# GD32A72_A74x register map
File version: 1.0
CPU: CM7 r2p1, little endian, MPU, FPU, DSP, 4 interrupt priority bits
Registers are 32-bit, read-write, reset 0x0 unless marked. A register's access mark holds for its fields unless they carry their own. Offsets are from the block's base; [hi:lo] are bit positions.

## ENET_MMC
Base 0x4000A700
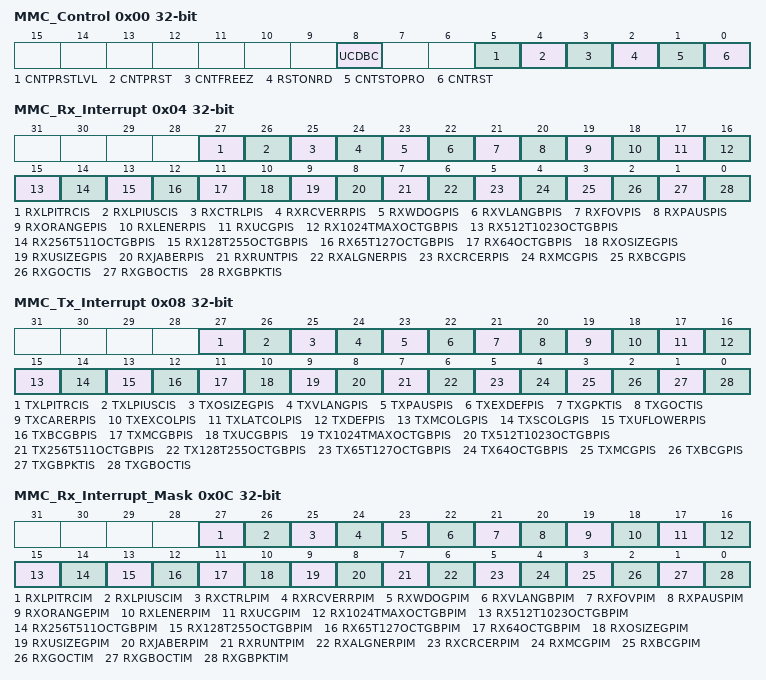
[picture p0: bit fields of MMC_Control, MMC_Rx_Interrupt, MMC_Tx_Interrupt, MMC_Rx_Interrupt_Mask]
0x00 MMC_Control
  [8] UCDBC — Update MMC Counters For Dropped Broadcast Packets
    0=DISABLE (Disabled); 1=ENABLE (Enabled)
  [5] CNTPRSTLVL — Full-Half Preset
    0=DISABLE (Disabled); 1=ENABLE (Enabled)
  [4] CNTPRST — Counters Preset
    0=DISABLE (Disabled); 1=ENABLE (Enabled)
  [3] CNTFREEZ — MMC Counter Freeze
    0=DISABLE (Disabled); 1=ENABLE (Enabled)
  [2] RSTONRD — Reset On Read
    0=DISABLE (Disabled); 1=ENABLE (Enabled)
  [1] CNTSTOPRO — Counter Stop Rollover
    0=DISABLE (Disabled); 1=ENABLE (Enabled)
  [0] CNTRST — Counters Reset
    0=DISABLE (Counters are not reset); 1=ENABLE (All counters are reset)
0x04 MMC_Rx_Interrupt ro — MMC Receive Interrupt
  [all] fields
    0=INACTIVE (Not detected); 1=ACTIVE (Detected)
  [27] RXLPITRCIS — MMC Receive LPI transition counter interrupt status
  [26] RXLPIUSCIS — MMC Receive LPI microsecond counter interrupt status
  [25] RXCTRLPIS — MMC Receive Control Packet Counter Interrupt Status
  [24] RXRCVERRPIS — MMC Receive Error Packet Counter Interrupt Status
  [23] RXWDOGPIS — MMC Receive Watchdog Error Packet Counter Interrupt Status
  [22] RXVLANGBPIS — MMC Receive VLAN Good Bad Packet Counter Interrupt Status
  [21] RXFOVPIS — MMC Receive FIFO Overflow Packet Counter Interrupt Status
  [20] RXPAUSPIS — MMC Receive Pause Packet Counter Interrupt Status
  [19] RXORANGEPIS — MMC Receive Out-Of-Range Error Packet Counter Interrupt Status
  [18] RXLENERPIS — MMC Receive Length Error Packet Counter Interrupt Status
  [17] RXUCGPIS — MMC Receive Unicast Good Packet Counter Interrupt Status
  [16] RX1024TMAXOCTGBPIS — MMC Receive 1024 To Maximum Octet Good Bad Packet Counter Interrupt Status
  [15] RX512T1023OCTGBPIS — MMC Receive 512 To 1023 Octet Good Bad Packet Counter Interrupt Status
  [14] RX256T511OCTGBPIS — MMC Receive 256 To 511 Octet Good Bad Packet Counter Interrupt Status
  [13] RX128T255OCTGBPIS — MMC Receive 128 To 255 Octet Good Bad Packet Counter Interrupt Status
  [12] RX65T127OCTGBPIS — MMC Receive 65 To 127 Octet Good Bad Packet Counter Interrupt Status
  [11] RX64OCTGBPIS — MMC Receive 64 Octet Good Bad Packet Counter Interrupt Status
  [10] RXOSIZEGPIS — MMC Receive Oversize Good Packet Counter Interrupt Status
  [9] RXUSIZEGPIS — MMC Receive Undersize Good Packet Counter Interrupt Status
  [8] RXJABERPIS — MMC Receive Jabber Error Packet Counter Interrupt Status
  [7] RXRUNTPIS — MMC Receive Runt Packet Counter Interrupt Status
  [6] RXALGNERPIS — MMC Receive Alignment Error Packet Counter Interrupt Status
  [5] RXCRCERPIS — MMC Receive CRC Error Packet Counter Interrupt Status
  [4] RXMCGPIS — MMC Receive Multicast Good Packet Counter Interrupt Status
  [3] RXBCGPIS — MMC Receive Broadcast Good Packet Counter Interrupt Status
  [2] RXGOCTIS — MMC Receive Good Octet Counter Interrupt Status
  [1] RXGBOCTIS — MMC Receive Good Bad Octet Counter Interrupt Status
  [0] RXGBPKTIS — MMC Receive Good Bad Packet Counter Interrupt Status
0x08 MMC_Tx_Interrupt ro — MMC Transmit Interrupt
  [all] fields
    0=INACTIVE (Not detected); 1=ACTIVE (Detected)
  [27] TXLPITRCIS — MMC Transmit LPI transition counter interrupt status
  [26] TXLPIUSCIS — MMC Transmit LPI microsecond counter interrupt status
  [25] TXOSIZEGPIS — MMC Transmit Oversize Good Packet Counter Interrupt Status
  [24] TXVLANGPIS — MMC Transmit VLAN Good Packet Counter Interrupt Status
  [23] TXPAUSPIS — MMC Transmit Pause Packet Counter Interrupt Status
  [22] TXEXDEFPIS — MMC Transmit Excessive Deferral Packet Counter Interrupt Status
  [21] TXGPKTIS — MMC Transmit Good Packet Counter Interrupt Status
  [20] TXGOCTIS — MMC Transmit Good Octet Counter Interrupt Status
  [19] TXCARERPIS — MMC Transmit Carrier Error Packet Counter Interrupt Status
  [18] TXEXCOLPIS — MMC Transmit Excessive Collision Packet Counter Interrupt Status
  [17] TXLATCOLPIS — MMC Transmit Late Collision Packet Counter Interrupt Status
  [16] TXDEFPIS — MMC Transmit Deferred Packet Counter Interrupt Status
  [15] TXMCOLGPIS — MMC Transmit Multiple Collision Good Packet Counter Interrupt Status
  [14] TXSCOLGPIS — MMC Transmit Single Collision Good Packet Counter Interrupt Status
  [13] TXUFLOWERPIS — MMC Transmit Underflow Error Packet Counter Interrupt Status
  [12] TXBCGBPIS — MMC Transmit Broadcast Good Bad Packet Counter Interrupt Status
  [11] TXMCGBPIS — MMC Transmit Multicast Good Bad Packet Counter Interrupt Status
  [10] TXUCGBPIS — MMC Transmit Unicast Good Bad Packet Counter Interrupt Status
  [9] TX1024TMAXOCTGBPIS — MMC Transmit 1024 To Maximum Octet Good Bad Packet Counter Interrupt Status
  [8] TX512T1023OCTGBPIS — MMC Transmit 512 To 1023 Octet Good Bad Packet Counter Interrupt Status
  [7] TX256T511OCTGBPIS — MMC Transmit 256 To 511 Octet Good Bad Packet Counter Interrupt Status
  [6] TX128T255OCTGBPIS — MMC Transmit 128 To 255 Octet Good Bad Packet Counter Interrupt Status
  [5] TX65T127OCTGBPIS — MMC Transmit 65 To 127 Octet Good Bad Packet Counter Interrupt Status
  [4] TX64OCTGBPIS — MMC Transmit 64-Octet Good Bad Packet Counter Interrupt Status
  [3] TXMCGPIS — MMC Transmit Multicast Good Packet Counter Interrupt Status
  [2] TXBCGPIS — MMC Transmit Broadcast Good Packet Counter Interrupt Status
  [1] TXGBPKTIS — MMC Transmit Good Bad Packet Counter Interrupt Status
  [0] TXGBOCTIS — MMC Transmit Good Bad Octet Counter Interrupt Status
0x0C MMC_Rx_Interrupt_Mask — MMC Receive Interrupt Mask
  [27] RXLPITRCIM — MMC Receive LPI transition counter interrupt Mask
    0=INACTIVE (Not detected); 1=ACTIVE (Detected)
  [26] RXLPIUSCIM — MMC Receive LPI microsecond counter interrupt Mask
    0=INACTIVE (Not detected); 1=ACTIVE (Detected)
  [25] RXCTRLPIM — MMC Receive Control Packet Counter Interrupt Mask
    0=DISABLE (Disabled); 1=ENABLE (Enabled)
  [24] RXRCVERRPIM — MMC Receive Error Packet Counter Interrupt Mask
    0=DISABLE (Disabled); 1=ENABLE (Enabled)
  [23] RXWDOGPIM — MMC Receive Watchdog Error Packet Counter Interrupt Mask
    0=DISABLE (Disabled); 1=ENABLE (Enabled)
  [22] RXVLANGBPIM — MMC Receive VLAN Good Bad Packet Counter Interrupt Mask
    0=DISABLE (Disabled); 1=ENABLE (Enabled)
  [21] RXFOVPIM — MMC Receive FIFO Overflow Packet Counter Interrupt Mask
    0=DISABLE (Disabled); 1=ENABLE (Enabled)
  [20] RXPAUSPIM — MMC Receive Pause Packet Counter Interrupt Mask
    0=DISABLE (Disabled); 1=ENABLE (Enabled)
  [19] RXORANGEPIM — MMC Receive Out-Of-Range Error Packet Counter Interrupt Mask
    0=DISABLE (Disabled); 1=ENABLE (Enabled)
  [18] RXLENERPIM — MMC Receive Length Error Packet Counter Interrupt Mask
    0=DISABLE (Disabled); 1=ENABLE (Enabled)
  [17] RXUCGPIM — MMC Receive Unicast Good Packet Counter Interrupt Mask
    0=DISABLE (Disabled); 1=ENABLE (Enabled)
  [16] RX1024TMAXOCTGBPIM — MMC Receive 1024 To Maximum Octet Good Bad Packet Counter Interrupt Mask
    0=DISABLE (Disabled); 1=ENABLE (Enabled)
  [15] RX512T1023OCTGBPIM — MMC Receive 512 To 1023 Octet Good Bad Packet Counter Interrupt Mask
    0=DISABLE (Disabled); 1=ENABLE (Enabled)
  [14] RX256T511OCTGBPIM — MMC Receive 256 To 511 Octet Good Bad Packet Counter Interrupt Mask
    0=DISABLE (Disabled); 1=ENABLE (Enabled)
  [13] RX128T255OCTGBPIM — MMC Receive 128 To 255 Octet Good Bad Packet Counter Interrupt Mask
    0=DISABLE (Disabled); 1=ENABLE (Enabled)
  [12] RX65T127OCTGBPIM — MMC Receive 65 To 127 Octet Good Bad Packet Counter Interrupt Mask
    0=DISABLE (Disabled); 1=ENABLE (Enabled)
  [11] RX64OCTGBPIM — MMC Receive 64-Octet Good Bad Packet Counter Interrupt Mask
    0=DISABLE (Disabled); 1=ENABLE (Enabled)
  [10] RXOSIZEGPIM — MMC Receive Oversize Good Packet Counter Interrupt Mask
    0=DISABLE (Disabled); 1=ENABLE (Enabled)
  [9] RXUSIZEGPIM — MMC Receive Undersize Good Packet Counter Interrupt Mask
    0=DISABLE (Disabled); 1=ENABLE (Enabled)
  [8] RXJABERPIM — MMC Receive Jabber Error Packet Counter Interrupt Mask
    0=DISABLE (Disabled); 1=ENABLE (Enabled)
  [7] RXRUNTPIM — MMC Receive Runt Packet Counter Interrupt Mask
    0=DISABLE (Disabled); 1=ENABLE (Enabled)
  [6] RXALGNERPIM — MMC Receive Alignment Error Packet Counter Interrupt Mask
    0=DISABLE (Disabled); 1=ENABLE (Enabled)
  [5] RXCRCERPIM — MMC Receive CRC Error Packet Counter Interrupt Mask
    0=DISABLE (Disabled); 1=ENABLE (Enabled)
  [4] RXMCGPIM — MMC Receive Multicast Good Packet Counter Interrupt Mask
    0=DISABLE (Disabled); 1=ENABLE (Enabled)
  [3] RXBCGPIM — MMC Receive Broadcast Good Packet Counter Interrupt Mask
    0=DISABLE (Disabled); 1=ENABLE (Enabled)
  [2] RXGOCTIM — MMC Receive Good Octet Counter Interrupt Mask
    0=DISABLE (Disabled); 1=ENABLE (Enabled)
  [1] RXGBOCTIM — MMC Receive Good Bad Octet Counter Interrupt Mask
    0=DISABLE (Disabled); 1=ENABLE (Enabled)
  [0] RXGBPKTIM — MMC Receive Good Bad Packet Counter Interrupt Mask
    0=DISABLE (Disabled); 1=ENABLE (Enabled)
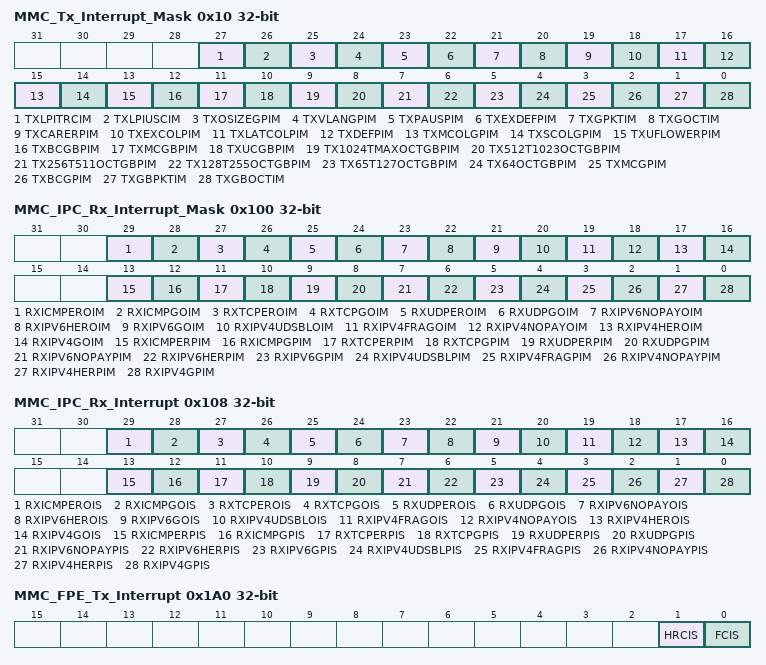
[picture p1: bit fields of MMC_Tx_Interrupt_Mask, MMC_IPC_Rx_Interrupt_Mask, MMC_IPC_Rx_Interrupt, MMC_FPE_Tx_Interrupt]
0x10 MMC_Tx_Interrupt_Mask — MMC Transmit Interrupt Mask
  [27] TXLPITRCIM — MMC Transmit LPI transition counter interrupt Mask
    0=INACTIVE (Not detected); 1=ACTIVE (Detected)
  [26] TXLPIUSCIM — MMC Transmit LPI microsecond counter interrupt Mask
    0=INACTIVE (Not detected); 1=ACTIVE (Detected)
  [25] TXOSIZEGPIM — MMC Transmit Oversize Good Packet Counter Interrupt Mask
    0=DISABLE (Disabled); 1=ENABLE (Enabled)
  [24] TXVLANGPIM — MMC Transmit VLAN Good Packet Counter Interrupt Mask
    0=DISABLE (Disabled); 1=ENABLE (Enabled)
  [23] TXPAUSPIM — MMC Transmit Pause Packet Counter Interrupt Mask
    0=DISABLE (Disabled); 1=ENABLE (Enabled)
  [22] TXEXDEFPIM — MMC Transmit Excessive Deferral Packet Counter Interrupt Mask
    0=DISABLE (Disabled); 1=ENABLE (Enabled)
  [21] TXGPKTIM — MMC Transmit Good Packet Counter Interrupt Mask
    0=DISABLE (Disabled); 1=ENABLE (Enabled)
  [20] TXGOCTIM — MMC Transmit Good Octet Counter Interrupt Mask
    0=DISABLE (Disabled); 1=ENABLE (Enabled)
  [19] TXCARERPIM — MMC Transmit Carrier Error Packet Counter Interrupt Mask
    0=DISABLE (Disabled); 1=ENABLE (Enabled)
  [18] TXEXCOLPIM — MMC Transmit Excessive Collision Packet Counter Interrupt Mask
    0=DISABLE (Disabled); 1=ENABLE (Enabled)
  [17] TXLATCOLPIM — MMC Transmit Late Collision Packet Counter Interrupt Mask
    0=DISABLE (Disabled); 1=ENABLE (Enabled)
  [16] TXDEFPIM — MMC Transmit Deferred Packet Counter Interrupt Mask
    0=DISABLE (Disabled); 1=ENABLE (Enabled)
  [15] TXMCOLGPIM — MMC Transmit Multiple Collision Good Packet Counter Interrupt Mask
    0=DISABLE (Disabled); 1=ENABLE (Enabled)
  [14] TXSCOLGPIM — MMC Transmit Single Collision Good Packet Counter Interrupt Mask
    0=DISABLE (Disabled); 1=ENABLE (Enabled)
  [13] TXUFLOWERPIM — MMC Transmit Underflow Error Packet Counter Interrupt Mask
    0=DISABLE (Disabled); 1=ENABLE (Enabled)
  [12] TXBCGBPIM — MMC Transmit Broadcast Good Bad Packet Counter Interrupt Mask
    0=DISABLE (Disabled); 1=ENABLE (Enabled)
  [11] TXMCGBPIM — MMC Transmit Multicast Good Bad Packet Counter Interrupt Mask
    0=DISABLE (Disabled); 1=ENABLE (Enabled)
  [10] TXUCGBPIM — MMC Transmit Unicast Good Bad Packet Counter Interrupt Mask
    0=DISABLE (Disabled); 1=ENABLE (Enabled)
  [9] TX1024TMAXOCTGBPIM — MMC Transmit 1024 To Maximum Octet Good Bad Packet Counter Interrupt Mask
    0=DISABLE (Disabled); 1=ENABLE (Enabled)
  [8] TX512T1023OCTGBPIM — MMC Transmit 512 To 1023 Octet Good Bad Packet Counter Interrupt Mask
    0=DISABLE (Disabled); 1=ENABLE (Enabled)
  [7] TX256T511OCTGBPIM — MMC Transmit 256 To 511 Octet Good Bad Packet Counter Interrupt Mask
    0=DISABLE (Disabled); 1=ENABLE (Enabled)
  [6] TX128T255OCTGBPIM — MMC Transmit 128 To 255 Octet Good Bad Packet Counter Interrupt Mask
    0=DISABLE (Disabled); 1=ENABLE (Enabled)
  [5] TX65T127OCTGBPIM — MMC Transmit 65 To 127 Octet Good Bad Packet Counter Interrupt Mask
    0=DISABLE (Disabled); 1=ENABLE (Enabled)
  [4] TX64OCTGBPIM — MMC Transmit 64-Octet Good Bad Packet Counter Interrupt Mask
    0=DISABLE (Disabled); 1=ENABLE (Enabled)
  [3] TXMCGPIM — MMC Transmit Multicast Good Packet Counter Interrupt Mask
    0=DISABLE (Disabled); 1=ENABLE (Enabled)
  [2] TXBCGPIM — MMC Transmit Broadcast Good Packet Counter Interrupt Mask
    0=DISABLE (Disabled); 1=ENABLE (Enabled)
  [1] TXGBPKTIM — MMC Transmit Good Bad Packet Counter Interrupt Mask
    0=DISABLE (Disabled); 1=ENABLE (Enabled)
  [0] TXGBOCTIM — MMC Transmit Good Bad Octet Counter Interrupt Mask
    0=DISABLE (Disabled); 1=ENABLE (Enabled)
0x14 Tx_Octet_Count_Good_Bad ro — Transmit Octet Count Good Bad
  [31:0] TXOCTGB
0x18 Tx_Packet_Count_Good_Bad ro — Transmit Packet Count Good Bad
  [31:0] TXPKTGB
0x1C Tx_Broadcast_Packets_Good ro — Transmit Broadcast Packets Good
  [31:0] TXBCASTG
0x20 Tx_Multicast_Packets_Good ro — Transmit Multicast Packets Good
  [31:0] TXMCASTG
0x24 Tx_64Octets_Packets_Good_Bad ro — Transmit 64-Octet Packets Good Bad
  [31:0] TX64OCTGB
0x28 Tx_65To127Octets_Packets_Good_Bad ro — Transmit 65 To 127 Octet Packets Good Bad
  [31:0] TX65_127OCTGB
0x2C Tx_128To255Octets_Packets_Good_Bad ro — Transmit 128 To 255 Octet Packets Good Bad
  [31:0] TX128_255OCTGB
0x30 Tx_256To511Octets_Packets_Good_Bad ro — Transmit 256 To 511 Octet Packets Good Bad
  [31:0] TX256_511OCTGB
0x34 Tx_512To1023Octets_Packets_Good_Bad ro — Transmit 512 To 1023 Octet Packets Good Bad
  [31:0] TX512_1023OCTGB
0x38 Tx_1024ToMaxOctets_Packets_Good_Bad ro — Transmit 1024 To Max Octet Packets Good Bad
  [31:0] TX1024_MAXOCTGB
0x3C Tx_Unicast_Packets_Good_Bad ro — Transmit Unicast Packets Good Bad
  [31:0] TXUCASTGB
0x40 Tx_Multicast_Packets_Good_Bad ro — Transmit Multicast Packets Good Bad
  [31:0] TXMCASTGB
0x44 Tx_Broadcast_Packets_Good_Bad ro — Transmit Broadcast Packets Good Bad
  [31:0] TXBCASTGB
0x48 Tx_Underflow_Error_Packets ro — Transmit Underflow Error Packets
  [31:0] TXUNDRFLW
0x4C Tx_Single_Collision_Good_Packets ro — Transmit Single Collision Good Packets
  [31:0] TXSNGLCOLG
0x50 Tx_Multiple_Collision_Good_Packets ro — Transmit Multiple Collision Good Packets
  [31:0] TXMULTCOLG
0x54 Tx_Deferred_Packets ro — Transmit Deferred Packets
  [31:0] TXDEFRD
0x58 Tx_Late_Collision_Packets ro — Transmit Late Collision Packets
  [31:0] TXLATECOL
0x5C Tx_Excessive_Collision_Packets ro — Transmit Excessive Collision Packets
  [31:0] TXEXSCOL
0x60 Tx_Carrier_Error_Packets ro — Transmit Carrier Error Packets
  [31:0] TXCARR
0x64 Tx_Octet_Count_Good ro — Transmit Octet Count Good
  [31:0] TXOCTG
0x68 Tx_Packet_Count_Good ro — Transmit Packet Count Good
  [31:0] TXPKTG
0x6C Tx_Excessive_Deferral_Error ro — Transmit Excessive Deferral Error
  [31:0] TXEXSDEF
0x70 Tx_Pause_Packets ro — Transmit Pause Packets
  [31:0] TXPAUSE
0x74 Tx_VLAN_Packets_Good ro — Transmit VLAN Packets Good
  [31:0] TXVLANG
0x78 Tx_OSize_Packets_Good ro — Transmit O Size Packets Good
  [31:0] TXOSIZG
0x80 Rx_Packets_Count_Good_Bad ro — Receive Packets Count Good Bad
  [31:0] RXPKTGB
0x84 Rx_Octet_Count_Good_Bad ro — Receive Octet Count Good Bad
  [31:0] RXOCTGB
0x88 Rx_Octet_Count_Good ro — Receive Octet Count Good
  [31:0] RXOCTG
0x8C Rx_Broadcast_Packets_Good ro — Receive Broadcast Packets Good
  [31:0] RXBCASTG
0x90 Rx_Multicast_Packets_Good ro — Receive Multicast Packets Good
  [31:0] RXMCASTG
0x94 Rx_CRC_Error_Packets ro — Receive CRC Error Packets
  [31:0] RXCRCERR
0x98 Rx_Alignment_Error_Packets ro — Receive Alignment Error Packets
  [31:0] RXALGNERR
0x9C Rx_Runt_Error_Packets ro — Receive Runt Error Packets
  [31:0] RXRUNTERR
0xA0 Rx_Jabber_Error_Packets ro — Receive Jabber Error Packets
  [31:0] RXJABERR
0xA4 Rx_Undersize_Packets_Good ro — Receive Undersize Packets Good
  [31:0] RXUNDERSZG
0xA8 Rx_Oversize_Packets_Good ro — Receive Oversize Packets Good
  [31:0] RXOVERSZG
0xAC Rx_64Octets_Packets_Good_Bad ro — Receive 64 Octets Packets Good Bad
  [31:0] RX64OCTGB
0xB0 Rx_65To127Octets_Packets_Good_Bad ro — Receive 65-127 Octets Packets Good Bad
  [31:0] RX65_127OCTGB
0xB4 Rx_128To255Octets_Packets_Good_Bad ro — Receive 128-255 Octets Packets Good Bad
  [31:0] RX128_255OCTGB
0xB8 Rx_256To511Octets_Packets_Good_Bad ro — Receive 256-511 Octets Packets Good Bad
  [31:0] RX256_511OCTGB
0xBC Rx_512To1023Octets_Packets_Good_Bad ro — Receive 512-1023 Octets Packets Good Bad
  [31:0] RX512_1023OCTGB
0xC0 Rx_1024ToMaxOctets_Packets_Good_Bad ro — Receive 1024 To Max Octets Good Bad
  [31:0] RX1024_MAXOCTGB — Receive 1024-Max Octets Good Bad
0xC4 Rx_Unicast_Packets_Good ro — Receive Unicast Packets Good
  [31:0] RXUCASTG
0xC8 Rx_Length_Error_Packets ro — Receive Length Error Packets
  [31:0] RXLENERR
0xCC Rx_Out_Of_Range_Type_Packets ro — Receive Out of Range Type Packet
  [31:0] RXOUTOFRNG
0xD0 Rx_Pause_Packets ro — Receive Pause Packets
  [31:0] RXPAUSEPKT
0xD4 Rx_FIFO_Overflow_Packets ro — Receive FIFO Overflow Packets
  [31:0] RXFIFOOVFL
0xD8 Rx_VLAN_Packets_Good_Bad ro — Receive VLAN Packets Good Bad
  [31:0] RXVLANPKTGB
0xDC Rx_Watchdog_Error_Packets ro — Receive Watchdog Error Packets
  [31:0] RXWDGERR
0xE0 Rx_Receive_Error_Packets ro — Receive Receive Error Packets
  [31:0] RXRCVERR
0xE4 Rx_Control_Packets_Good ro — Receive Control Packets Good
  [31:0] RXCTRLG
0xEC Tx_LPI_USEC_Cntr ro — Transmit LPI Microseconds Counter register
  [31:0] TXLPIUSC — Tx LPI Microseconds Counter
0xF0 Tx_LPI_Tran_Cntr ro — Transmit LPI Transition Counter register
  [31:0] TXLPITRC — Tx LPI Transition counter
0xF4 Rx_LPI_USEC_Cntr ro — Receive LPI Microseconds Counter register
  [31:0] RXLPIUSC — Rx LPI Microseconds Counter
0xF8 Rx_LPI_Tran_Cntr ro — Receive LPI Transition Counter register
  [31:0] RXLPITRC — Rx LPI Transition counter
0x100 MMC_IPC_Rx_Interrupt_Mask — MMC IPC receive interrupt mask register
  [29] RXICMPEROIM — MMC Receive ICMP Error Octet Counter Interrupt Mask
  [28] RXICMPGOIM — MMC Receive ICMP Good Octet Counter Interrupt Mask
  [27] RXTCPEROIM — MMC Receive TCP Error Octet Counter Interrupt Mask
  [26] RXTCPGOIM — MMC Receive TCP Good Octet Counter Interrupt Mask
  [25] RXUDPEROIM — MMC Receive UDP Error Octet Counter Interrupt Mask
  [24] RXUDPGOIM — MMC Receive UDP Good Octet Counter Interrupt Mask
  [23] RXIPV6NOPAYOIM — MMC Receive IPV6 No Payload Octet Counter Interrupt Mask
  [22] RXIPV6HEROIM — MMC Receive IPV6 Header Error Octet Counter Interrupt Mask
  [21] RXIPV6GOIM — MMC Receive IPV6 Good Octet Counter Interrupt Mask
  [20] RXIPV4UDSBLOIM — MMC Receive IPV4 UDP Checksum Disabled Octet Counter Interrupt Mask
  [19] RXIPV4FRAGOIM — MMC Receive IPV4 Fragmented Octet Counter Interrupt Mask
  [18] RXIPV4NOPAYOIM — MMC Receive IPV4 No Payload Octet Counter Interrupt Mask
  [17] RXIPV4HEROIM — MMC Receive IPV4 Header Error Octet Counter Interrupt Mask
  [16] RXIPV4GOIM — MMC Receive IPV4 Good Octet Counter Interrupt Mask
  [13] RXICMPERPIM — MMC Receive ICMP Error Packet Counter Interrupt Mask
  [12] RXICMPGPIM — MMC Receive ICMP Good Packet Counter Interrupt Mask
  [11] RXTCPERPIM — MMC Receive TCP Error Packet Counter Interrupt Mask
  [10] RXTCPGPIM — MMC Receive TCP Good Packet Counter Interrupt Mask
  [9] RXUDPERPIM — MMC Receive UDP Error Packet Counter Interrupt Mask
  [8] RXUDPGPIM — MMC Receive UDP Good Packet Counter Interrupt Mask
  [7] RXIPV6NOPAYPIM — MMC Receive IPV6 No Payload Packet Counter Interrupt Mask
  [6] RXIPV6HERPIM — MMC Receive IPV6 Header Error Packet Counter Interrupt Mask
  [5] RXIPV6GPIM — MMC Receive IPV6 Good Packet Counter Interrupt Mask
  [4] RXIPV4UDSBLPIM — MMC Receive IPV4 UDP Checksum Disabled Packet Counter Interrupt Mask
  [3] RXIPV4FRAGPIM — MMC Receive IPV4 Fragmented Packet Counter Interrupt Mask
  [2] RXIPV4NOPAYPIM — MMC Receive IPV4 No Payload Packet Counter Interrupt Mask
  [1] RXIPV4HERPIM — MMC Receive IPV4 Header Error Packet Counter Interrupt Mask
  [0] RXIPV4GPIM — MMC Receive IPV4 Good Packet Counter Interrupt Mask
0x108 MMC_IPC_Rx_Interrupt — MMC IPC receive interrupt register
  [29] RXICMPEROIS — MMC Receive ICMP Error Octet Counter Interrupt Status
  [28] RXICMPGOIS — MMC Receive ICMP Good Octet Counter Interrupt Status
  [27] RXTCPEROIS — MMC Receive TCP Error Octet Counter Interrupt Status
  [26] RXTCPGOIS — MMC Receive TCP Good Octet Counter Interrupt Status
  [25] RXUDPEROIS — MMC Receive UDP Error Octet Counter Interrupt Status
  [24] RXUDPGOIS — MMC Receive UDP Good Octet Counter Interrupt Status
  [23] RXIPV6NOPAYOIS — MMC Receive IPV6 No Payload Octet Counter Interrupt Status
  [22] RXIPV6HEROIS — MMC Receive IPV6 Header Error Octet Counter Interrupt Status
  [21] RXIPV6GOIS — MMC Receive IPV6 Good Octet Counter Interrupt Status
  [20] RXIPV4UDSBLOIS — MMC Receive IPV4 UDP Checksum Disabled Octet Counter Interrupt Status
  [19] RXIPV4FRAGOIS — MMC Receive IPV4 Fragmented Octet Counter Interrupt Status
  [18] RXIPV4NOPAYOIS — MMC Receive IPV4 No Payload Octet Counter Interrupt Status
  [17] RXIPV4HEROIS — MMC Receive IPV4 Header Error Octet Counter Interrupt Status
  [16] RXIPV4GOIS — MMC Receive IPV4 Good Octet Counter Interrupt Status
  [13] RXICMPERPIS — MMC Receive ICMP Error Packet Counter Interrupt Status
  [12] RXICMPGPIS — MMC Receive ICMP Good Packet Counter Interrupt Status
  [11] RXTCPERPIS — MMC Receive TCP Error Packet Counter Interrupt Status
  [10] RXTCPGPIS — MMC Receive TCP Good Packet Counter Interrupt Status
  [9] RXUDPERPIS — MMC Receive UDP Error Packet Counter Interrupt Status
  [8] RXUDPGPIS — MC Receive UDP Good Packet Counter Interrupt Status
  [7] RXIPV6NOPAYPIS — MMC Receive IPV6 No Payload Packet Counter Interrupt Status
  [6] RXIPV6HERPIS — MMC Receive IPV6 Header Error Packet Counter Interrupt Status
  [5] RXIPV6GPIS — MMC Receive IPV6 Good Packet Counter Interrupt Status
  [4] RXIPV4UDSBLPIS — MMC Receive IPV4 UDP Checksum Disabled Packet Counter Interrupt Status
  [3] RXIPV4FRAGPIS — MMC Receive IPV4 Fragmented Packet Counter Interrupt Status
  [2] RXIPV4NOPAYPIS — MMC Receive IPV4 No Payload Packet Counter Interrupt Status
  [1] RXIPV4HERPIS — MMC Receive IPV4 Header Error Packet Counter Interrupt Status
  [0] RXIPV4GPIS — MMC Receive IPV4 Good Packet Counter Interrupt Status
0x110 RxIPv4_Good_Packets ro — Receive ipv4 good packets register
  [31:0] RXIPV4GDPKT — RxIPv4 Good Packets
0x114 RxIPv4_Header_Error_Packets ro — Receive ipv4 header errors packets register
  [31:0] RXIPV4HDRERRPKT — RxIPv4 Header Error Packets
0x118 RxIPv4_No_Payload_Packets ro — Receive ipv4 no payload packets register
  [31:0] RXIPV4NOPAYPKT — RxIPv4 Payload Packets
0x11C RxIPv4_Fragmented_Packets ro — Receive fragmented IPv4 packets register
  [31:0] RXIPV4FRAGPKT — RxIPv4 Fragmented Packets
0x120 RxIPv4_UDP_Checksum_Disabled_Packets ro — Receive ipv4 udp checksum disable packets register
  [31:0] RXIPV4UDSBLPKT — RxIPv4 UDP Checksum Disabled Packets
0x124 RxIPv6_Good_Packets ro — Receive ipv6 good packets register
  [31:0] RXIPV6GDPKT — RxIPv6 Good Packets
0x128 RxIPv6_Header_Error_Packets ro — Receive ipv6 header errors packets register
  [31:0] RXIPV6HDRERRPKT — RxIPv6 Header Error Packets
0x12C RxIPv6_No_Payload_Packets ro — Receive ipv6 no payload packets register
  [31:0] RXIPV6NOPAYPKT — RxIPv6 Payload Packets
0x130 RxUDP_Good_Packets ro — Receive udp packets good register
  [31:0] RXUDPGDPKT — RxUDP Good Packets
0x134 RxUDP_Error_Packets ro — Receive udp checksum errors packets register
  [31:0] RXUDPERRPKT — RxUDP Error Packets
0x138 RxTCP_Good_Packets ro — Receive tcp packets good register
  [31:0] RXTCPGDPKT — RxTCP Good Packets
0x13C RxTCP_Error_Packets ro — Receive tcp checksum errors packets register
  [31:0] RXTCPERRPKT — RxTCP Error Packets
0x140 RxICMP_Good_Packets ro — Receive icmp packets good register
  [31:0] RXICMPGDPKT — RxICMP Good Packets
0x144 RxICMP_Error_Packets ro — Receive icmp checksum errors packets register
  [31:0] RXICMPERRPKT — RxICMP Error Packets
0x150 RxIPv4_Good_Octets ro — Receive ipv4 good octets register
  [31:0] RXIPV4GDOCT — RxIPv4 Good Octets
0x154 RxIPv4_Header_Error_Octets ro — Receive ipv4 header errors octets register
  [31:0] RXIPV4HDRERROCT — RxIPv4 Header Error Octets
0x158 RxIPv4_No_Payload_Octets ro — Receive ipv4 no payload octets register
  [31:0] RXIPV4NOPAYOCT — RxIPv4 No Payload Octets
0x15C RxIPv4_Fragmented_Octets ro — Receive fragmented IPv4 octets register
  [31:0] RXIPV4FRAGOCT — RxIPv4 Fragmented Octets
0x160 RxIPv4_UDP_Checksum_Disable_Octets ro — Receive ipv4 udp checksum disable octets register
  [31:0] RXIPV4UDSBLOCT — RxIPv4 UDP Checksum Disable Octets
0x164 RxIPv6_Good_Octets ro — Receive ipv6 good octets register
  [31:0] RXIPV6GDOCT — RxIPv6 Good Octets
0x168 RxIPv6_Header_Error_Octets ro — Receive ipv6 header errors octets register
  [31:0] RXIPV6HDRERROCT — RxIPv6 Header Error Octets
0x16C RxIPv6_No_Payload_Octets ro — Receive ipv6 no payload octets register
  [31:0] RXIPV6NOPAYOCT — RxIPv6 Payload Octets
0x170 RxUDP_Good_Octets ro — Receive udp good octets register
  [31:0] RXUDPGDOCT — RxUDP Good Octets
0x174 RxUDP_Error_Octets ro — Receive udp checksum errors octets register
  [31:0] RXUDPERROCT — RxUDP Error Octets
0x178 RxTCP_Good_Octets ro — Receive tcp good octets register
  [31:0] RXTCPGDOCT — RxTCP Good Octets
0x17C RxTCP_Error_Octets ro — Receive tcp checksum errors octets register
  [31:0] RXTCPERROCT — RxTCP Error Octets
0x180 RxICMP_Good_Octets ro — Receive icmp good octets register
  [31:0] RXICMPGDOCT — RxICMP Good Octets
0x184 RxICMP_Error_Octets ro — Receive icmp checksum errors octets register
  [31:0] RXICMPERROCT — RxICMP Error Octets
0x1A0 MMC_FPE_Tx_Interrupt ro — MMC Transmit FPE Fragment Counter Interrupt Status
  [1] HRCIS — MMC Transmit Hold Request Counter Interrupt Status
    0=INACTIVE (Not detected); 1=ACTIVE (Detected)
  [0] FCIS — MMC Transmit FPE Fragment Counter Interrupt Status
    0=INACTIVE (Not detected); 1=ACTIVE (Detected)
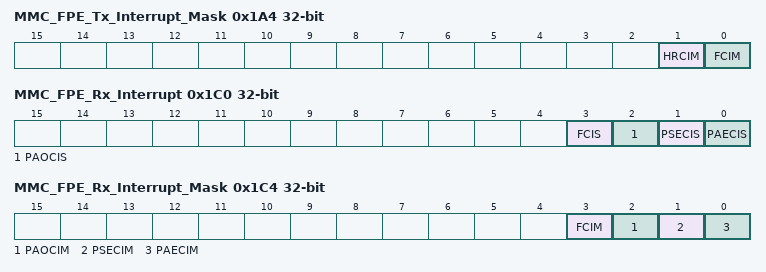
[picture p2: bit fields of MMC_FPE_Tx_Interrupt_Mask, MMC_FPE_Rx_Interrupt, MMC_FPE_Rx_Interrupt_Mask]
0x1A4 MMC_FPE_Tx_Interrupt_Mask — MMC FPE Transmit Interrupt Mask
  [1] HRCIM — MMC Transmit Hold Request Counter Interrupt Mask
    0=DISABLE (Disabled); 1=ENABLE (Enabled)
  [0] FCIM — MMC Transmit Fragment Counter Interrupt Mask
    0=DISABLE (Disabled); 1=ENABLE (Enabled)
0x1A8 MMC_Tx_FPE_Fragment_Cntr ro — Transmit FPE Fragment Counter
  [31:0] TXFFC
0x1AC MMC_Tx_Hold_Req_Cntr ro — Transmit Hold Request Counter
  [31:0] TXHRC
0x1C0 MMC_FPE_Rx_Interrupt ro — MMC Receive Packet Assembly Error Counter Interrupt Status
  [all] fields
    0=INACTIVE (Not detected); 1=ACTIVE (Detected)
  [3] FCIS — MMC Receive FPE Fragment Counter Interrupt Status
  [2] PAOCIS — MMC Receive Packet Assembly OK Counter Interrupt Status
  [1] PSECIS — MMC Receive, Transmit, Packet SMD Error Counter Interrupt Status
  [0] PAECIS — MMC Receive, transmit, Packet Assembly Error Counter Interrupt Status
0x1C4 MMC_FPE_Rx_Interrupt_Mask — MMC FPE Receive Interrupt Mask
  [all] fields
    0=DISABLE (Disabled); 1=ENABLE (Enabled)
  [3] FCIM — MMC Receive FPE Fragment Counter Interrupt Mask
  [2] PAOCIM — MMC Receive Packet Assembly OK Counter Interrupt Mask
  [1] PSECIM — MMC Receive Packet SMD Error Counter Interrupt Mask
  [0] PAECIM — MMC receive Packet Assembly Error Counter Interrupt Mask
0x1C8 MMC_Rx_Packet_Assembly_Err_Cntr ro — MMC Receive Packet Assembly Error Counter
  [31:0] PAEC — Packet Assembly Error Counter
0x1CC MMC_Rx_Packet_SMD_Err_Cntr ro — MMC Receive Packet SMD Error Counter
  [31:0] PSEC — Packet SMD Error Counter
0x1D0 MMC_Rx_Packet_Assembly_OK_Cntr ro — MMC Receive Packet Assembly OK Counter
  [31:0] PAOC — Packet Assembly OK Counter
0x1D4 MMC_Rx_FPE_Fragment_Cntr ro — MMC Receive FPE Fragment Counter
  [31:0] FFC — FPE Fragment Counter
